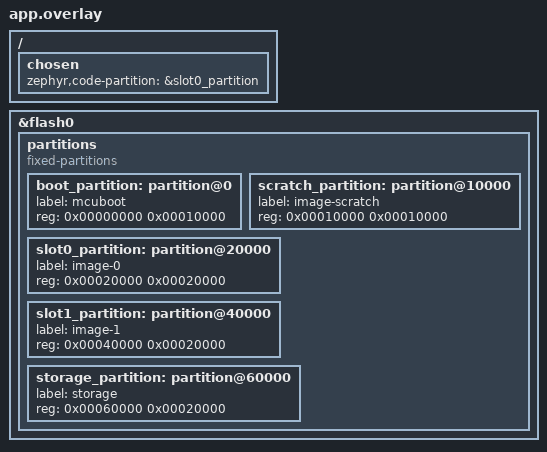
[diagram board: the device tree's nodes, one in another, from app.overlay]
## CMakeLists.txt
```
cmake_minimum_required(VERSION 3.20.0)
find_package(Zephyr REQUIRED HINTS $ENV{ZEPHYR_BASE})
project(cerberus)
target_sources(app PRIVATE src/main.c)
```

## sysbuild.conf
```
SB_CONFIG_BOOTLOADER_MCUBOOT=y
SB_CONFIG_BOOT_SIGNATURE_TYPE_ECDSA_P256=y
SB_CONFIG_BOOT_SIGNATURE_KEY_FILE="/home/socrates/zephyr_workspace/cerberus/keys/cerberus_key.pem"
```

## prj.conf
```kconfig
CONFIG_BOOTLOADER_MCUBOOT=y
CONFIG_IMG_MANAGER=y
CONFIG_FLASH=y
CONFIG_FLASH_MAP=y
CONFIG_STREAM_FLASH=y
CONFIG_CONSOLE=y
CONFIG_UART_CONSOLE=y
```

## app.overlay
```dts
/ {
	chosen {
		/* Tells Zephyr to boot your application from Slot 0 */
		zephyr,code-partition = &slot0_partition;
	};
};

&flash0 {
	partitions {
		compatible = "fixed-partitions";
		#address-cells = <1>;
		#size-cells = <1>;

		/* Sectors 0, 1, 2, 3 (16KB each = 64KB Total) */
		boot_partition: partition@0 {
			label = "mcuboot";
			reg = <0x00000000 0x00010000>;
		};

		/* Sector 4 (64KB Total) */
		scratch_partition: partition@10000 {
			label = "image-scratch";
			reg = <0x00010000 0x00010000>;
		};

		/* Sector 5 (128KB Total) */
		slot0_partition: partition@20000 {
			label = "image-0";
			reg = <0x00020000 0x00020000>;
		};

		/* Sector 6 (128KB Total) */
		slot1_partition: partition@40000 {
			label = "image-1";
			reg = <0x00040000 0x00020000>;
		};

		/* Sector 7 (128KB Total) */
		storage_partition: partition@60000 {
			label = "storage";
			reg = <0x00060000 0x00020000>;
		};
	};
};
```

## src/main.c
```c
#include <stdbool.h>
#include <zephyr/kernel.h>
#include <zephyr/dfu/mcuboot.h>

#define APP_VERSION "3.1.0"

int main(void)
{
    printk("\n-------------------------\n");
    printk("Firmware version: %s\n", APP_VERSION);

    if (!boot_is_img_confirmed()) {
        int rc = boot_write_img_confirmed();
        printk("Confirming image: %s (rc=%d)\n", rc == 0 ? "OK" : "FAIL", rc);
    }

    printk("Image confirmed: %s\n", boot_is_img_confirmed() ? "YES" : "NO");

    while (1) {
        printk("[HEARTBEAT] Firmware %s is running\n", APP_VERSION);
        k_sleep(K_SECONDS(5));
    }
    return 0;
}
```
